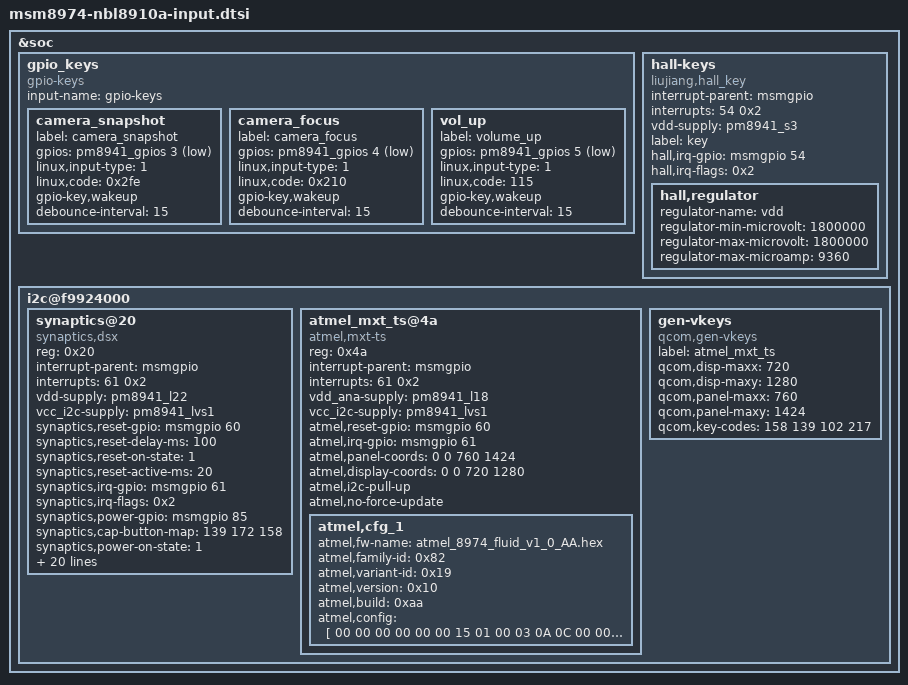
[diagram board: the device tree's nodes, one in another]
/* Copyright (c) 2018, The Linux Foundation. All rights reserved.
 *
 * This program is free software; you can redistribute it and/or modify
 * it under the terms of the GNU General Public License version 2 and
 * only version 2 as published by the Free Software Foundation.
 *
 * This program is distributed in the hope that it will be useful,
 * but WITHOUT ANY WARRANTY; without even the implied warranty of
 * MERCHANTABILITY or FITNESS FOR A PARTICULAR PURPOSE.  See the
 * GNU General Public License for more details.
 */

&soc {
	gpio_keys {
		compatible = "gpio-keys";
		input-name = "gpio-keys";

		camera_snapshot {
			label = "camera_snapshot";
			gpios = <&pm8941_gpios 3 0x1>;
			linux,input-type = <1>;
			linux,code = <0x2fe>;
			gpio-key,wakeup;
			debounce-interval = <15>;
		};

		camera_focus {
			label = "camera_focus";
			gpios = <&pm8941_gpios 4 0x1>;
			linux,input-type = <1>;
			linux,code = <0x210>;
			gpio-key,wakeup;
			debounce-interval = <15>;
		};

		vol_up {
			label = "volume_up";
			gpios = <&pm8941_gpios 5 0x1>;
			linux,input-type = <1>;
			linux,code = <115>;
			gpio-key,wakeup;
			debounce-interval = <15>;
		};
	};

	hall-keys {
		interrupt-parent = <&msmgpio>;
		interrupts = <54 0x2>;
		vdd-supply = <&pm8941_s3>;
		compatible = "liujiang,hall_key";
		label = "key";
		hall,irq-gpio = <&msmgpio 54 0x00>;
		hall,irq-flags = <0x2>;
		hall,regulator {
			regulator-name = "vdd";
			regulator-min-microvolt = <1800000>;
			regulator-max-microvolt = <1800000>;
			regulator-max-microamp = <9360>;
		};
	};

	i2c@f9924000 {
		synaptics@20 {
			compatible = "synaptics,dsx";
			reg = <0x20>;
			interrupt-parent = <&msmgpio>;
			interrupts = <61 0x2>;
	        	vdd-supply = <&pm8941_l22>;
		        vcc_i2c-supply = <&pm8941_lvs1>;

		        synaptics,reset-gpio = <&msmgpio 60 0x00>;
			synaptics,reset-delay-ms = <100>;
			synaptics,reset-on-state = <1>;
			synaptics,reset-active-ms = <20>;
			synaptics,irq-gpio = <&msmgpio 61 0x00>;
			synaptics,irq-flags = <0x2>;
			synaptics,power-gpio = <&msmgpio 85 0x00>;
			synaptics,cap-button-map = <139 172 158>; 
			synaptics,power-on-state = <1>;
			synaptics,power-delay-ms = <160>;
			synaptics,max-y-for-2d = <2560>; /* remove if no virtual buttons */
			synaptics,fw-image-name1 = "PR1782558-s3508r_OW_000000D2.img";
			synaptics,fw-image-name2 = "PR1782558-s3508r_TW_000000BF.img";
			synaptics,fw-image-name3 = "PR1782558-s3508r_TB_000000BF.img";
			synaptics,fw-image-name4 = "PR1782558-s3508r_TW_000000BF.img";
			synaptics,fw-image-name5 = "PR1782558-s3508r_OB_000000D2.img";
			synaptics,fw-image-name6 = "PR1782558-s3508r_OW_000000D2.img";
			synaptics,fw-image-name7 = "PR1782558-s3508r_OG_000000D2.img";
			synaptics,fw-image-name8 = "PR1782558-s3508r_TG_000000BF.img";
			synaptics,vir-button-codes = <102 100 900 100 60 158 300 900 100 60>;
		};
		atmel_mxt_ts@4a {
			compatible = "atmel,mxt-ts";
			reg = <0x4a>;
			interrupt-parent = <&msmgpio>;
			interrupts = <61 0x2>;
			vdd_ana-supply = <&pm8941_l18>;
			vcc_i2c-supply = <&pm8941_lvs1>;
			atmel,reset-gpio = <&msmgpio 60 0x00>;
			atmel,irq-gpio = <&msmgpio 61 0x00>;
			atmel,panel-coords = <0  0 760 1424>;
			atmel,display-coords = <0 0 720 1280>;
			atmel,i2c-pull-up;
			atmel,no-force-update;
			atmel,cfg_1 {
				atmel,fw-name = "atmel_8974_fluid_v1_0_AA.hex";
				atmel,family-id = <0x82>;
				atmel,variant-id = <0x19>;
				atmel,version = <0x10>;
				atmel,build = <0xaa>;
				atmel,config = [
					/* Object 6, Instance = 0 */
					00 00 00 00 00 00
					/* Object 38, Instance = 0 */
					15 01 00 03 0A 0C 00 00
					/* Object 7, Instance = 0 */
					20 08 32 03
					/* Object 8, Instance = 0 */
					0F 00 0A 0A 00 00 0A 0A 00 00
					/* Object 9, Instance = 0 */
					83 00 00 18 0E 00 70 46 02 01
					00 0A 03 31 04 05 0A 0A 90 05
					F8 02 05 F1 F1 0F 00 00 08 2D
					12 06 00 00 00 01
					/* Object 15, Instance = 0 */
					00 00 00 00 00 00 00 00 00 00
					00
					/* Object 18, Instance = 0 */
					00 00
					/* Object 19, Instance = 0 */
					00 00 00 00 00 00
					/* Object 23, Instance = 0 */
					00 00 00 00 00 00 00 00 00 00
					00 00 00 00 00
					/* Object 25, Instance = 0 */
					00 00 00 00 00 00 00 00 00 00
					00 00 00 00 00
					/* Object 40, Instance = 0 */
					00 00 00 00 00
					/* Object 42, Instance = 0 */
					33 1E 19 10 80 00 00 00 FF 00
					/* Object 46, Instance = 0 */
					00 00 10 10 00 00 03 00 00 01
					/* Object 47, Instance = 0 */
					08 0A 28 0A 02 0A 00 8C 00 20
					00 00 00
					/* Object 55, Instance = 0 */
					00 00 00 00 00 00
					/* Object 56, Instance = 0 */
					00 00 00 18 05 05 05 05 05 05
					05 05 05 05 05 05 05 05 05 05
					05 05 05 05 05 05 05 05 00 00
					00 00 00 00 00 00 00 00 00 00
					00 00
					/* Object 57, Instance = 0 */
					00 00 00
					/* Object 61, Instance = 0 */
					00 00 00 00 00
					/* Object 62, Instance = 0 */
					01 2A 00 16 00 00 00 00 0B 01
					02 03 04 08 00 00 08 10 18 05
					00 0A 05 05 50 14 19 34 1A 7F
					00 00 00 00 00 00 00 00 00 30
					05 02 00 01 00 05 00 00 00 00
					00 00 00 00
					];
			};
		};
		gen-vkeys {
		compatible = "qcom,gen-vkeys";
		label = "atmel_mxt_ts";
		qcom,disp-maxx = <720>;
		qcom,disp-maxy = <1280>;
		qcom,panel-maxx = <760>;
		qcom,panel-maxy = <1424>;
		qcom,key-codes = <158 139 102 217>;
		};
	};
};
